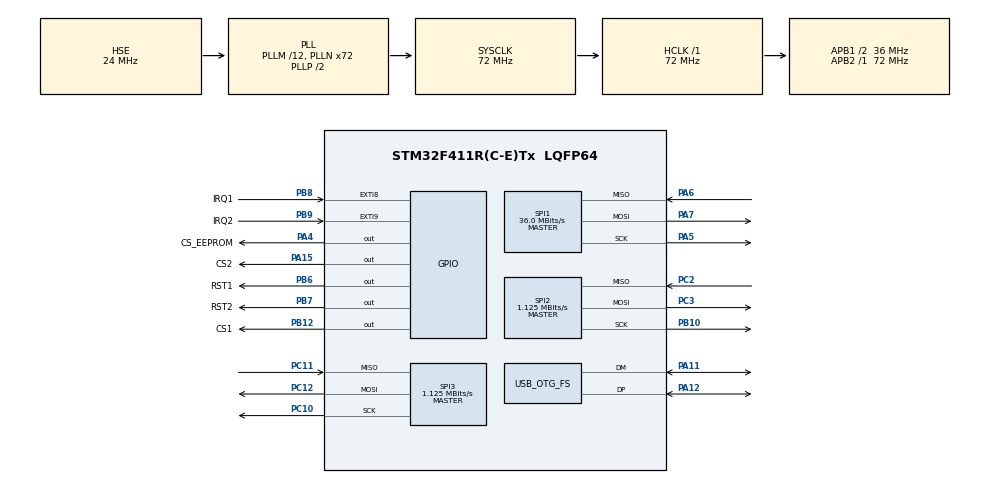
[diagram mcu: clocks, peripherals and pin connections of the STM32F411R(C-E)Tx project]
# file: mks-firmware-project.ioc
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Mcu.Family=STM32F4
Mcu.Name=STM32F411R(C-E)Tx
Mcu.Package=LQFP64
NVIC.OTG_FS_IRQn=true\:0\:0\:false\:false\:true\:false\:true\:true
NVIC.PriorityGroup=NVIC_PRIORITYGROUP_4
PA11.Mode=Device_Only
PA11.Signal=USB_OTG_FS_DM
PA12.Mode=Device_Only
PA12.Signal=USB_OTG_FS_DP
PA13.Mode=Serial_Wire
PA13.Signal=SYS_JTMS-SWDIO
PA14.Mode=Serial_Wire
PA14.Signal=SYS_JTCK-SWCLK
PA15.GPIO_Label=CS2
PA15.PinState=GPIO_PIN_SET
PA15.Signal=GPIO_Output
PA4.GPIO_Label=CS_EEPROM
PA4.PinState=GPIO_PIN_SET
PA4.Signal=GPIO_Output
PA5.Mode=Full_Duplex_Master
PA5.Signal=SPI1_SCK
PA6.Mode=Full_Duplex_Master
PA6.Signal=SPI1_MISO
PA7.Mode=Full_Duplex_Master
PA7.Signal=SPI1_MOSI
PB10.Mode=Full_Duplex_Master
PB10.Signal=SPI2_SCK
PB12.GPIO_Label=CS1
PB12.PinState=GPIO_PIN_SET
PB12.Signal=GPIO_Output
PB6.GPIO_Label=RST1
PB6.Signal=GPIO_Output
PB7.GPIO_Label=RST2
PB7.Signal=GPIO_Output
PB8.GPIO_Label=IRQ1
PB8.GPIO_PuPd=GPIO_PULLDOWN
PB8.Signal=GPXTI8
PB9.GPIO_Label=IRQ2
PB9.GPIO_PuPd=GPIO_PULLDOWN
PB9.Signal=GPXTI9
PC10.Mode=Full_Duplex_Master
PC10.Signal=SPI3_SCK
PC11.Mode=Full_Duplex_Master
PC11.Signal=SPI3_MISO
PC12.Mode=Full_Duplex_Master
PC12.Signal=SPI3_MOSI
PC2.Mode=Full_Duplex_Master
PC2.Signal=SPI2_MISO
PC3.Mode=Full_Duplex_Master
PC3.Signal=SPI2_MOSI
PH0\ -\ OSC_IN.Mode=HSE-External-Oscillator
PH0\ -\ OSC_IN.Signal=RCC_OSC_IN
PH1\ -\ OSC_OUT.Mode=HSE-External-Oscillator
PH1\ -\ OSC_OUT.Signal=RCC_OSC_OUT
ProjectManager.HeapSize=0x200
ProjectManager.StackSize=0x400
ProjectManager.TargetToolchain=STM32CubeIDE
RCC.48MHZClocksFreq_Value=48000000
RCC.AHBFreq_Value=72000000
RCC.APB1CLKDivider=RCC_HCLK_DIV2
RCC.APB1Freq_Value=36000000
RCC.APB1TimFreq_Value=72000000
RCC.APB2Freq_Value=72000000
RCC.APB2TimFreq_Value=72000000
RCC.CortexFreq_Value=72000000
RCC.HCLKFreq_Value=72000000
RCC.HSE_VALUE=24000000
RCC.HSI_VALUE=16000000
RCC.LSE_VALUE=32768
RCC.PLLM=12
RCC.PLLN=72
RCC.PLLQ=3
RCC.SYSCLKFreq_VALUE=72000000
RCC.SYSCLKSource=RCC_SYSCLKSOURCE_PLLCLK
RCC.VCOOutputFreq_Value=144000000
SPI1.CalculateBaudRate=36.0 MBits/s
SPI1.Direction=SPI_DIRECTION_2LINES
SPI1.Mode=SPI_MODE_MASTER
SPI1.VirtualType=VM_MASTER
SPI2.BaudRatePrescaler=SPI_BAUDRATEPRESCALER_32
SPI2.CalculateBaudRate=1.125 MBits/s
SPI2.Direction=SPI_DIRECTION_2LINES
SPI2.Mode=SPI_MODE_MASTER
SPI2.VirtualType=VM_MASTER
SPI3.BaudRatePrescaler=SPI_BAUDRATEPRESCALER_32
SPI3.CalculateBaudRate=1.125 MBits/s
SPI3.Direction=SPI_DIRECTION_2LINES
SPI3.Mode=SPI_MODE_MASTER
SPI3.VirtualType=VM_MASTER
USB_DEVICE.CLASS_NAME_FS=CDC
USB_DEVICE.VirtualMode=Cdc
USB_DEVICE.VirtualModeFS=Cdc_FS
USB_OTG_FS.VirtualMode=Device_Only
VP_USB_DEVICE_VS_USB_DEVICE_CDC_FS.Mode=CDC_FS
board=custom

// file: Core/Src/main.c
/* USER CODE BEGIN Header */
/**
  ******************************************************************************
  * @file           : main.c
  * @brief          : Main program body
  ******************************************************************************
  * @attention
  *
  * Copyright (c) 2026 STMicroelectronics.
  * All rights reserved.
  *
  * This software is licensed under terms that can be found in the LICENSE file
  * in the root directory of this software component.
  * If no LICENSE file comes with this software, it is provided AS-IS.
  *
  ******************************************************************************
  */
/* USER CODE END Header */
#include "main.h"
#include "usb_device.h"

/* USER CODE BEGIN Includes */
#include "deca_port.h"
#include "board_config.h"
#include "protocol.h"
extern int bringup_read_devids(void);
/* USER CODE END Includes */

SPI_HandleTypeDef hspi1;
SPI_HandleTypeDef hspi2;
SPI_HandleTypeDef hspi3;

void SystemClock_Config(void);
static void MX_GPIO_Init(void);
static void MX_SPI1_Init(void);
static void MX_SPI2_Init(void);
static void MX_SPI3_Init(void);

int main(void)
{

  /* MCU Configuration--------------------------------------------------------*/

  /* Reset of all peripherals, Initializes the Flash interface and the Systick. */
  HAL_Init();

  /* Configure the system clock */
  SystemClock_Config();

  /* Initialize all configured peripherals */
  MX_GPIO_Init();
  MX_SPI1_Init();
  MX_SPI2_Init();
  MX_SPI3_Init();
  MX_USB_DEVICE_Init();
  /* USER CODE BEGIN 2 */
  int ok = bringup_read_devids();   /* Для самого первого раза поставить точку останова здесь */
  (void)ok;                          /* смотреть g_devid[] в отладчике */

  /* Слой протокола (bare-metal): парсер кормится из CDC_Receive_FS,
   * ответы уходят через CDC_Transmit_FS. Обработчики — Шаг 2. */
  PROTOCOL_Init();
  PROTOCOL_RegisterAllHandlers();
  /* USER CODE END 2 */

  /* Infinite loop */
  while (1)
  {

    /* USER CODE BEGIN 3 */
    PROTOCOL_PollRx();      /* разбор накопленных USB-байт в thread mode */
    PROTOCOL_PollRadio();   /* обслуживание радиоприёма (RXFCG/ошибки) */
    PROTOCOL_PollTx();      /* обслуживание периодической передачи (TX_PERIODIC) */
  }
  /* USER CODE END 3 */
}

void SystemClock_Config(void)
{
  RCC_OscInitTypeDef RCC_OscInitStruct = {0};
  RCC_ClkInitTypeDef RCC_ClkInitStruct = {0};

  /** Configure the main internal regulator output voltage
  */
  __HAL_RCC_PWR_CLK_ENABLE();
  __HAL_PWR_VOLTAGESCALING_CONFIG(PWR_REGULATOR_VOLTAGE_SCALE1);

  /** Initializes the RCC Oscillators according to the specified parameters
  * in the RCC_OscInitTypeDef structure.
  */
  RCC_OscInitStruct.OscillatorType = RCC_OSCILLATORTYPE_HSE;
  RCC_OscInitStruct.HSEState = RCC_HSE_ON;
  RCC_OscInitStruct.PLL.PLLState = RCC_PLL_ON;
  RCC_OscInitStruct.PLL.PLLSource = RCC_PLLSOURCE_HSE;
  RCC_OscInitStruct.PLL.PLLM = 12;
  RCC_OscInitStruct.PLL.PLLN = 72;
  RCC_OscInitStruct.PLL.PLLP = RCC_PLLP_DIV2;
  RCC_OscInitStruct.PLL.PLLQ = 3;
  if (HAL_RCC_OscConfig(&RCC_OscInitStruct) != HAL_OK)
  {
    Error_Handler();
  }

  /** Initializes the CPU, AHB and APB buses clocks
  */
  RCC_ClkInitStruct.ClockType = RCC_CLOCKTYPE_HCLK|RCC_CLOCKTYPE_SYSCLK
                              |RCC_CLOCKTYPE_PCLK1|RCC_CLOCKTYPE_PCLK2;
  RCC_ClkInitStruct.SYSCLKSource = RCC_SYSCLKSOURCE_PLLCLK;
  RCC_ClkInitStruct.AHBCLKDivider = RCC_SYSCLK_DIV1;
  RCC_ClkInitStruct.APB1CLKDivider = RCC_HCLK_DIV2;
  RCC_ClkInitStruct.APB2CLKDivider = RCC_HCLK_DIV1;

  if (HAL_RCC_ClockConfig(&RCC_ClkInitStruct, FLASH_LATENCY_2) != HAL_OK)
  {
    Error_Handler();
  }
}

static void MX_SPI1_Init(void)
{

  /* SPI1 parameter configuration*/
  hspi1.Instance = SPI1;
  hspi1.Init.Mode = SPI_MODE_MASTER;
  hspi1.Init.Direction = SPI_DIRECTION_2LINES;
  hspi1.Init.DataSize = SPI_DATASIZE_8BIT;
  hspi1.Init.CLKPolarity = SPI_POLARITY_LOW;
  hspi1.Init.CLKPhase = SPI_PHASE_1EDGE;
  hspi1.Init.NSS = SPI_NSS_SOFT;
  hspi1.Init.BaudRatePrescaler = SPI_BAUDRATEPRESCALER_2;
  hspi1.Init.FirstBit = SPI_FIRSTBIT_MSB;
  hspi1.Init.TIMode = SPI_TIMODE_DISABLE;
  hspi1.Init.CRCCalculation = SPI_CRCCALCULATION_DISABLE;
  hspi1.Init.CRCPolynomial = 10;
  if (HAL_SPI_Init(&hspi1) != HAL_OK)
  {
    Error_Handler();
  }

}

static void MX_SPI2_Init(void)
{

  /* SPI2 parameter configuration*/
  hspi2.Instance = SPI2;
  hspi2.Init.Mode = SPI_MODE_MASTER;
  hspi2.Init.Direction = SPI_DIRECTION_2LINES;
  hspi2.Init.DataSize = SPI_DATASIZE_8BIT;
  hspi2.Init.CLKPolarity = SPI_POLARITY_LOW;
  hspi2.Init.CLKPhase = SPI_PHASE_1EDGE;
  hspi2.Init.NSS = SPI_NSS_SOFT;
  hspi2.Init.BaudRatePrescaler = SPI_BAUDRATEPRESCALER_32;
  hspi2.Init.FirstBit = SPI_FIRSTBIT_MSB;
  hspi2.Init.TIMode = SPI_TIMODE_DISABLE;
  hspi2.Init.CRCCalculation = SPI_CRCCALCULATION_DISABLE;
  hspi2.Init.CRCPolynomial = 10;
  if (HAL_SPI_Init(&hspi2) != HAL_OK)
  {
    Error_Handler();
  }

}

static void MX_SPI3_Init(void)
{

  /* SPI3 parameter configuration*/
  hspi3.Instance = SPI3;
  hspi3.Init.Mode = SPI_MODE_MASTER;
  hspi3.Init.Direction = SPI_DIRECTION_2LINES;
  hspi3.Init.DataSize = SPI_DATASIZE_8BIT;
  hspi3.Init.CLKPolarity = SPI_POLARITY_LOW;
  hspi3.Init.CLKPhase = SPI_PHASE_1EDGE;
  hspi3.Init.NSS = SPI_NSS_SOFT;
  hspi3.Init.BaudRatePrescaler = SPI_BAUDRATEPRESCALER_32;
  hspi3.Init.FirstBit = SPI_FIRSTBIT_MSB;
  hspi3.Init.TIMode = SPI_TIMODE_DISABLE;
  hspi3.Init.CRCCalculation = SPI_CRCCALCULATION_DISABLE;
  hspi3.Init.CRCPolynomial = 10;
  if (HAL_SPI_Init(&hspi3) != HAL_OK)
  {
    Error_Handler();
  }

}

static void MX_GPIO_Init(void)
{
  GPIO_InitTypeDef GPIO_InitStruct = {0};

  /* GPIO Ports Clock Enable */
  __HAL_RCC_GPIOH_CLK_ENABLE();
  __HAL_RCC_GPIOC_CLK_ENABLE();
  __HAL_RCC_GPIOA_CLK_ENABLE();
  __HAL_RCC_GPIOB_CLK_ENABLE();

  /*Configure GPIO pin Output Level */
  HAL_GPIO_WritePin(GPIOA, CS_EEPROM_Pin|CS2_Pin, GPIO_PIN_SET);

  /*Configure GPIO pin Output Level */
  HAL_GPIO_WritePin(CS1_GPIO_Port, CS1_Pin, GPIO_PIN_SET);

  /*Configure GPIO pin Output Level */
  HAL_GPIO_WritePin(GPIOB, RST1_Pin|RST2_Pin, GPIO_PIN_RESET);

  /*Configure GPIO pins : CS_EEPROM_Pin CS2_Pin */
  GPIO_InitStruct.Pin = CS_EEPROM_Pin|CS2_Pin;
  GPIO_InitStruct.Mode = GPIO_MODE_OUTPUT_PP;
  GPIO_InitStruct.Pull = GPIO_NOPULL;
  GPIO_InitStruct.Speed = GPIO_SPEED_FREQ_LOW;
  HAL_GPIO_Init(GPIOA, &GPIO_InitStruct);

  /*Configure GPIO pins : CS1_Pin RST1_Pin RST2_Pin */
  GPIO_InitStruct.Pin = CS1_Pin|RST1_Pin|RST2_Pin;
  GPIO_InitStruct.Mode = GPIO_MODE_OUTPUT_PP;
  GPIO_InitStruct.Pull = GPIO_NOPULL;
  GPIO_InitStruct.Speed = GPIO_SPEED_FREQ_LOW;
  HAL_GPIO_Init(GPIOB, &GPIO_InitStruct);

  /*Configure GPIO pins : IRQ1_Pin IRQ2_Pin */
  GPIO_InitStruct.Pin = IRQ1_Pin|IRQ2_Pin;
  GPIO_InitStruct.Mode = GPIO_MODE_IT_RISING;
  GPIO_InitStruct.Pull = GPIO_PULLDOWN;
  HAL_GPIO_Init(GPIOB, &GPIO_InitStruct);

}

void Error_Handler(void)
{
  __disable_irq();
  while (1)
  {
  }
}
